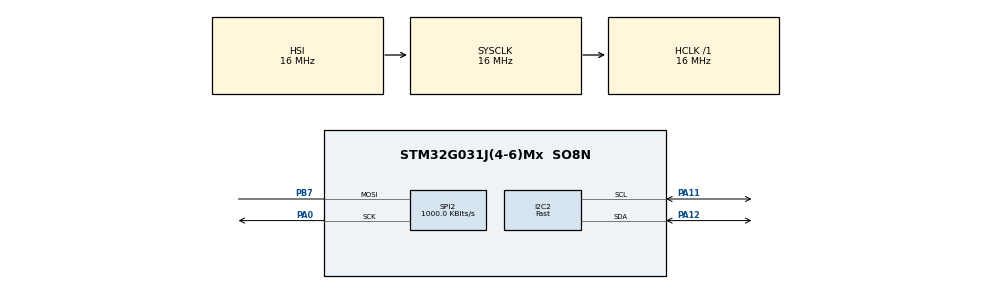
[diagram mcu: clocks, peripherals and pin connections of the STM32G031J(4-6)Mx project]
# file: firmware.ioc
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Dma.I2C2_RX.1.Direction=DMA_PERIPH_TO_MEMORY
Dma.I2C2_RX.1.EventEnable=DISABLE
Dma.I2C2_RX.1.Instance=DMA1_Channel2
Dma.I2C2_RX.1.MemDataAlignment=DMA_MDATAALIGN_BYTE
Dma.I2C2_RX.1.MemInc=DMA_MINC_ENABLE
Dma.I2C2_RX.1.Mode=DMA_NORMAL
Dma.I2C2_RX.1.PeriphDataAlignment=DMA_PDATAALIGN_BYTE
Dma.I2C2_RX.1.PeriphInc=DMA_PINC_DISABLE
Dma.I2C2_RX.1.Polarity=HAL_DMAMUX_REQ_GEN_RISING
Dma.I2C2_RX.1.Priority=DMA_PRIORITY_LOW
Dma.I2C2_RX.1.RequestNumber=1
Dma.I2C2_RX.1.SignalID=NONE
Dma.I2C2_RX.1.SyncEnable=DISABLE
Dma.I2C2_RX.1.SyncPolarity=HAL_DMAMUX_SYNC_NO_EVENT
Dma.I2C2_RX.1.SyncRequestNumber=1
Dma.I2C2_RX.1.SyncSignalID=NONE
Dma.I2C2_TX.2.Direction=DMA_MEMORY_TO_PERIPH
Dma.I2C2_TX.2.EventEnable=DISABLE
Dma.I2C2_TX.2.Instance=DMA1_Channel3
Dma.I2C2_TX.2.MemDataAlignment=DMA_MDATAALIGN_BYTE
Dma.I2C2_TX.2.MemInc=DMA_MINC_ENABLE
Dma.I2C2_TX.2.Mode=DMA_NORMAL
Dma.I2C2_TX.2.PeriphDataAlignment=DMA_PDATAALIGN_BYTE
Dma.I2C2_TX.2.PeriphInc=DMA_PINC_DISABLE
Dma.I2C2_TX.2.Polarity=HAL_DMAMUX_REQ_GEN_RISING
Dma.I2C2_TX.2.Priority=DMA_PRIORITY_LOW
Dma.I2C2_TX.2.RequestNumber=1
Dma.I2C2_TX.2.SignalID=NONE
Dma.I2C2_TX.2.SyncEnable=DISABLE
Dma.I2C2_TX.2.SyncPolarity=HAL_DMAMUX_SYNC_NO_EVENT
Dma.I2C2_TX.2.SyncRequestNumber=1
Dma.I2C2_TX.2.SyncSignalID=NONE
Dma.Request0=SPI2_TX
Dma.Request1=I2C2_RX
Dma.Request2=I2C2_TX
Dma.SPI2_TX.0.Direction=DMA_MEMORY_TO_PERIPH
Dma.SPI2_TX.0.EventEnable=DISABLE
Dma.SPI2_TX.0.Instance=DMA1_Channel1
Dma.SPI2_TX.0.MemDataAlignment=DMA_MDATAALIGN_BYTE
Dma.SPI2_TX.0.MemInc=DMA_MINC_ENABLE
Dma.SPI2_TX.0.Mode=DMA_NORMAL
Dma.SPI2_TX.0.PeriphDataAlignment=DMA_PDATAALIGN_BYTE
Dma.SPI2_TX.0.PeriphInc=DMA_PINC_DISABLE
Dma.SPI2_TX.0.Polarity=HAL_DMAMUX_REQ_GEN_RISING
Dma.SPI2_TX.0.Priority=DMA_PRIORITY_LOW
Dma.SPI2_TX.0.RequestNumber=1
Dma.SPI2_TX.0.SignalID=NONE
Dma.SPI2_TX.0.SyncEnable=DISABLE
Dma.SPI2_TX.0.SyncPolarity=HAL_DMAMUX_SYNC_NO_EVENT
Dma.SPI2_TX.0.SyncRequestNumber=1
Dma.SPI2_TX.0.SyncSignalID=NONE
I2C2.I2C_Speed_Mode=I2C_Fast
I2C2.Timing=0x0010061A
Mcu.Family=STM32G0
Mcu.Name=STM32G031J(4-6)Mx
Mcu.Package=SO8N
NVIC.DMA1_Channel1_IRQn=true\:0\:0\:false\:false\:true\:false\:true
NVIC.DMA1_Channel2_3_IRQn=true\:0\:0\:false\:false\:true\:false\:true
PA0.Mode=Simplex_Bidirectional_Master
PA0.Signal=SPI2_SCK
PA11\ [PA9].Mode=I2C
PA11\ [PA9].Signal=I2C2_SCL
PA12\ [PA10].Mode=I2C
PA12\ [PA10].Signal=I2C2_SDA
PA13.Mode=Serial_Wire
PA13.Signal=SYS_SWDIO
PA14-BOOT0.Mode=Serial_Wire
PA14-BOOT0.Signal=SYS_SWCLK
PB7.Mode=Simplex_Bidirectional_Master
PB7.Signal=SPI2_MOSI
ProjectManager.HeapSize=0x200
ProjectManager.StackSize=0x400
ProjectManager.TargetToolchain=STM32CubeIDE
RCC.ADCFreq_Value=16000000
RCC.AHBFreq_Value=16000000
RCC.CortexFreq_Value=16000000
RCC.EXTERNAL_CLOCK_VALUE=12288000
RCC.HCLKFreq_Value=16000000
RCC.HSE_VALUE=8000000
RCC.HSI_VALUE=16000000
RCC.LSE_VALUE=32768
RCC.SYSCLKFreq_VALUE=16000000
RCC.VCOOutputFreq_Value=128000000
SPI2.BaudRatePrescaler=SPI_BAUDRATEPRESCALER_16
SPI2.CalculateBaudRate=1000.0 KBits/s
SPI2.Direction=SPI_DIRECTION_1LINE
SPI2.Mode=SPI_MODE_MASTER
SPI2.NSSPMode=SPI_NSS_PULSE_DISABLE
SPI2.VirtualType=VM_MASTER
board=custom

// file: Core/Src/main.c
/* USER CODE BEGIN Header */
/**
  ******************************************************************************
  * @file           : main.c
  * @brief          : Main program body
  ******************************************************************************
  * @attention
  *
  * <h2><center>&copy; Copyright (c) 2020 STMicroelectronics.
  * All rights reserved.</center></h2>
  *
  * This software component is licensed by ST under BSD 3-Clause license,
  * the "License"; You may not use this file except in compliance with the
  * License. You may obtain a copy of the License at:
  *                        opensource.org/licenses/BSD-3-Clause
  *
  ******************************************************************************
  */
/* USER CODE END Header */
#include "main.h"

/* USER CODE BEGIN Includes */
#include "app.h"
/* USER CODE END Includes */

I2C_HandleTypeDef hi2c2;
DMA_HandleTypeDef hdma_i2c2_rx;
DMA_HandleTypeDef hdma_i2c2_tx;

SPI_HandleTypeDef hspi2;
DMA_HandleTypeDef hdma_spi2_tx;

/* USER CODE BEGIN PV */
SPI_HandleTypeDef *getSPI() {return &hspi2;}
I2C_HandleTypeDef *getI2C() {return &hi2c2;}
/* USER CODE END PV */

void SystemClock_Config(void);
static void MX_GPIO_Init(void);
static void MX_DMA_Init(void);
static void MX_I2C2_Init(void);
static void MX_SPI2_Init(void);

int main(void)
{

  /* MCU Configuration--------------------------------------------------------*/

  /* Reset of all peripherals, Initializes the Flash interface and the Systick. */
  HAL_Init();

  /* Configure the system clock */
  SystemClock_Config();

  /* Initialize all configured peripherals */
  MX_GPIO_Init();
  MX_DMA_Init();
  MX_I2C2_Init();
  MX_SPI2_Init();
  /* USER CODE BEGIN 2 */
  initApp();
  /* USER CODE END 2 */

  /* Infinite loop */
  while (1)
  {

    /* USER CODE BEGIN 3 */
	  run();
  }
  /* USER CODE END 3 */
}

void SystemClock_Config(void)
{
  RCC_OscInitTypeDef RCC_OscInitStruct = {0};
  RCC_ClkInitTypeDef RCC_ClkInitStruct = {0};

  /** Configure the main internal regulator output voltage
  */
  HAL_PWREx_ControlVoltageScaling(PWR_REGULATOR_VOLTAGE_SCALE1);
  /** Initializes the RCC Oscillators according to the specified parameters
  * in the RCC_OscInitTypeDef structure.
  */
  RCC_OscInitStruct.OscillatorType = RCC_OSCILLATORTYPE_HSI;
  RCC_OscInitStruct.HSIState = RCC_HSI_ON;
  RCC_OscInitStruct.HSIDiv = RCC_HSI_DIV1;
  RCC_OscInitStruct.HSICalibrationValue = RCC_HSICALIBRATION_DEFAULT;
  RCC_OscInitStruct.PLL.PLLState = RCC_PLL_NONE;
  if (HAL_RCC_OscConfig(&RCC_OscInitStruct) != HAL_OK)
  {
    Error_Handler();
  }
  /** Initializes the CPU, AHB and APB buses clocks
  */
  RCC_ClkInitStruct.ClockType = RCC_CLOCKTYPE_HCLK|RCC_CLOCKTYPE_SYSCLK
                              |RCC_CLOCKTYPE_PCLK1;
  RCC_ClkInitStruct.SYSCLKSource = RCC_SYSCLKSOURCE_HSI;
  RCC_ClkInitStruct.AHBCLKDivider = RCC_SYSCLK_DIV1;
  RCC_ClkInitStruct.APB1CLKDivider = RCC_HCLK_DIV1;

  if (HAL_RCC_ClockConfig(&RCC_ClkInitStruct, FLASH_LATENCY_0) != HAL_OK)
  {
    Error_Handler();
  }
}

static void MX_I2C2_Init(void)
{

  hi2c2.Instance = I2C2;
  hi2c2.Init.Timing = 0x0010061A;
  hi2c2.Init.OwnAddress1 = 0;
  hi2c2.Init.AddressingMode = I2C_ADDRESSINGMODE_7BIT;
  hi2c2.Init.DualAddressMode = I2C_DUALADDRESS_DISABLE;
  hi2c2.Init.OwnAddress2 = 0;
  hi2c2.Init.OwnAddress2Masks = I2C_OA2_NOMASK;
  hi2c2.Init.GeneralCallMode = I2C_GENERALCALL_DISABLE;
  hi2c2.Init.NoStretchMode = I2C_NOSTRETCH_DISABLE;
  if (HAL_I2C_Init(&hi2c2) != HAL_OK)
  {
    Error_Handler();
  }
  /** Configure Analogue filter
  */
  if (HAL_I2CEx_ConfigAnalogFilter(&hi2c2, I2C_ANALOGFILTER_ENABLE) != HAL_OK)
  {
    Error_Handler();
  }
  /** Configure Digital filter
  */
  if (HAL_I2CEx_ConfigDigitalFilter(&hi2c2, 0) != HAL_OK)
  {
    Error_Handler();
  }

}

static void MX_SPI2_Init(void)
{

  /* SPI2 parameter configuration*/
  hspi2.Instance = SPI2;
  hspi2.Init.Mode = SPI_MODE_MASTER;
  hspi2.Init.Direction = SPI_DIRECTION_1LINE;
  hspi2.Init.DataSize = SPI_DATASIZE_8BIT;
  hspi2.Init.CLKPolarity = SPI_POLARITY_LOW;
  hspi2.Init.CLKPhase = SPI_PHASE_1EDGE;
  hspi2.Init.NSS = SPI_NSS_SOFT;
  hspi2.Init.BaudRatePrescaler = SPI_BAUDRATEPRESCALER_16;
  hspi2.Init.FirstBit = SPI_FIRSTBIT_MSB;
  hspi2.Init.TIMode = SPI_TIMODE_DISABLE;
  hspi2.Init.CRCCalculation = SPI_CRCCALCULATION_DISABLE;
  hspi2.Init.CRCPolynomial = 7;
  hspi2.Init.CRCLength = SPI_CRC_LENGTH_DATASIZE;
  hspi2.Init.NSSPMode = SPI_NSS_PULSE_DISABLE;
  if (HAL_SPI_Init(&hspi2) != HAL_OK)
  {
    Error_Handler();
  }

}

static void MX_DMA_Init(void)
{

  /* DMA controller clock enable */
  __HAL_RCC_DMA1_CLK_ENABLE();

  /* DMA interrupt init */
  /* DMA1_Channel1_IRQn interrupt configuration */
  HAL_NVIC_SetPriority(DMA1_Channel1_IRQn, 0, 0);
  HAL_NVIC_EnableIRQ(DMA1_Channel1_IRQn);
  /* DMA1_Channel2_3_IRQn interrupt configuration */
  HAL_NVIC_SetPriority(DMA1_Channel2_3_IRQn, 0, 0);
  HAL_NVIC_EnableIRQ(DMA1_Channel2_3_IRQn);

}

static void MX_GPIO_Init(void)
{
  GPIO_InitTypeDef GPIO_InitStruct = {0};

  /* GPIO Ports Clock Enable */
  __HAL_RCC_GPIOC_CLK_ENABLE();
  __HAL_RCC_GPIOB_CLK_ENABLE();
  __HAL_RCC_GPIOF_CLK_ENABLE();
  __HAL_RCC_GPIOA_CLK_ENABLE();

  /*Configure GPIO pin : PC14 */
  GPIO_InitStruct.Pin = GPIO_PIN_14;
  GPIO_InitStruct.Mode = GPIO_MODE_ANALOG;
  GPIO_InitStruct.Pull = GPIO_NOPULL;
  HAL_GPIO_Init(GPIOC, &GPIO_InitStruct);

  /*Configure GPIO pins : PB8 PB9 PB0 PB1
                           PB5 PB6 */
  GPIO_InitStruct.Pin = GPIO_PIN_8|GPIO_PIN_9|GPIO_PIN_0|GPIO_PIN_1
                          |GPIO_PIN_5|GPIO_PIN_6;
  GPIO_InitStruct.Mode = GPIO_MODE_ANALOG;
  GPIO_InitStruct.Pull = GPIO_NOPULL;
  HAL_GPIO_Init(GPIOB, &GPIO_InitStruct);

  /*Configure GPIO pin : PF2 */
  GPIO_InitStruct.Pin = GPIO_PIN_2;
  GPIO_InitStruct.Mode = GPIO_MODE_ANALOG;
  GPIO_InitStruct.Pull = GPIO_NOPULL;
  HAL_GPIO_Init(GPIOF, &GPIO_InitStruct);

  /*Configure GPIO pins : PA1 PA2 PA8 PA15 */
  GPIO_InitStruct.Pin = GPIO_PIN_1|GPIO_PIN_2|GPIO_PIN_8|GPIO_PIN_15;
  GPIO_InitStruct.Mode = GPIO_MODE_ANALOG;
  GPIO_InitStruct.Pull = GPIO_NOPULL;
  HAL_GPIO_Init(GPIOA, &GPIO_InitStruct);

}

void Error_Handler(void)
{
}

/************************ (C) COPYRIGHT STMicroelectronics *****END OF FILE****/
